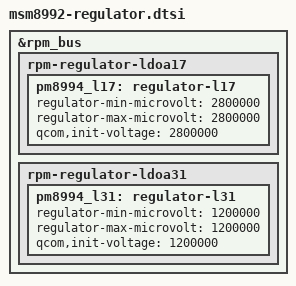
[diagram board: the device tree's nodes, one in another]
/* Copyright (c) 2014-2015, The Linux Foundation. All rights reserved.
 *
 * This program is free software; you can redistribute it and/or modify
 * it under the terms of the GNU General Public License version 2 and
 * only version 2 as published by the Free Software Foundation.
 *
 * This program is distributed in the hope that it will be useful,
 * but WITHOUT ANY WARRANTY; without even the implied warranty of
 * MERCHANTABILITY or FITNESS FOR A PARTICULAR PURPOSE.  See the
 * GNU General Public License for more details.
 */

&rpm_bus {
	rpm-regulator-ldoa17 {
		pm8994_l17: regulator-l17 {
			regulator-min-microvolt = <2800000>;
			regulator-max-microvolt = <2800000>;
			qcom,init-voltage = <2800000>;
		};
	};

	rpm-regulator-ldoa31 {
		pm8994_l31: regulator-l31 {
			regulator-min-microvolt = <1200000>;
			regulator-max-microvolt = <1200000>;
			qcom,init-voltage = <1200000>;
		};
	};
};
